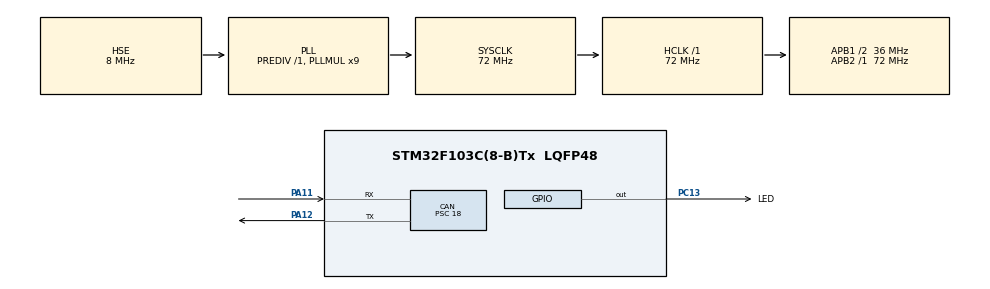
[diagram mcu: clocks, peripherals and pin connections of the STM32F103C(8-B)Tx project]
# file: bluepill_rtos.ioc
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CAN.BS1=CAN_BS1_14TQ
CAN.BS2=CAN_BS2_5TQ
CAN.CalculateBaudRate=100000
CAN.CalculateTimeBit=10000.00
CAN.CalculateTimeQuantum=500.0
CAN.Prescaler=18
FREERTOS.Tasks01=defaultTask,0,128,StartDefaultTask,Default,NULL,Dynamic,NULL,NULL;myTask02,-3,128,StartTask02,Default,NULL,Dynamic,NULL,NULL;myTask03,-3,128,StartTask03,Default,NULL,Dynamic,NULL,NULL
Mcu.Family=STM32F1
Mcu.Name=STM32F103C(8-B)Tx
Mcu.Package=LQFP48
NVIC.PriorityGroup=NVIC_PRIORITYGROUP_4
NVIC.TIM1_UP_IRQn=true\:0\:0\:false\:false\:true\:false\:false\:true
NVIC.TimeBase=TIM1_UP_IRQn
NVIC.TimeBaseIP=TIM1
NVIC.USB_LP_CAN1_RX0_IRQn=true\:5\:0\:false\:false\:true\:true\:true\:true
PA11.Mode=CAN_Activate
PA11.Signal=CAN_RX
PA12.Mode=CAN_Activate
PA12.Signal=CAN_TX
PA13.Mode=Serial_Wire
PA13.Signal=SYS_JTMS-SWDIO
PA14.Mode=Serial_Wire
PA14.Signal=SYS_JTCK-SWCLK
PC13-TAMPER-RTC.GPIO_Label=LED
PC13-TAMPER-RTC.Signal=GPIO_Output
PD0-OSC_IN.Mode=HSE-External-Oscillator
PD0-OSC_IN.Signal=RCC_OSC_IN
PD1-OSC_OUT.Mode=HSE-External-Oscillator
PD1-OSC_OUT.Signal=RCC_OSC_OUT
ProjectManager.HeapSize=0x200
ProjectManager.StackSize=0x400
ProjectManager.TargetToolchain=MDK-ARM V5
RCC.AHBFreq_Value=72000000
RCC.APB1CLKDivider=RCC_HCLK_DIV2
RCC.APB1Freq_Value=36000000
RCC.APB1TimFreq_Value=72000000
RCC.APB2Freq_Value=72000000
RCC.APB2TimFreq_Value=72000000
RCC.HCLKFreq_Value=72000000
RCC.PLLMUL=RCC_PLL_MUL9
RCC.PLLSourceVirtual=RCC_PLLSOURCE_HSE
RCC.SYSCLKFreq_VALUE=72000000
RCC.SYSCLKSource=RCC_SYSCLKSOURCE_PLLCLK
RCC.USBFreq_Value=72000000
VP_FREERTOS_VS_CMSIS_V1.Mode=CMSIS_V1
VP_SYS_VS_tim1.Mode=TIM1
board=custom

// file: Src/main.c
/* USER CODE BEGIN Header */
/**
  ******************************************************************************
  * @file           : main.c
  * @brief          : Main program body
  ******************************************************************************
  * @attention
  *
  * <h2><center>&copy; Copyright (c) 2021 STMicroelectronics.
  * All rights reserved.</center></h2>
  *
  * This software component is licensed by ST under Ultimate Liberty license
  * SLA0044, the "License"; You may not use this file except in compliance with
  * the License. You may obtain a copy of the License at:
  *                             www.st.com/SLA0044
  *
  ******************************************************************************
  */
/* USER CODE END Header */
#include "main.h"
#include "cmsis_os.h"
#include "can.h"
#include "gpio.h"
#include "time.h" //사용자 지정
#include <stdio.h> //지정하고 있는 라이브러리 경로

/* USER CODE BEGIN PV */
volatile uint8_t can1_rx0_flag =0; //컴파일러에게 최적화 x

/* USER CODE END PV */

void SystemClock_Config(void);
void MX_FREERTOS_Init(void);

/* USER CODE BEGIN 0 */
uint8_t tt=0;
char str[10];
/* USER CODE END 0 */

int main(void)
{

  /* MCU Configuration--------------------------------------------------------*/

  /* Reset of all peripherals, Initializes the Flash interface and the Systick. */
  HAL_Init();

  /* Configure the system clock */
  SystemClock_Config();

  /* Initialize all configured peripherals */
  MX_GPIO_Init();
  MX_CAN_Init();
  /* USER CODE BEGIN 2 */

	/*receive code 102,106,10A,10E 수신 */
	canFilter1.FilterMaskIdHigh = 0x7F3 <<5; //레지스터 id부분 상위11비트에 할당
	canFilter1.FilterIdHigh= 0x106 <<5; //5bit 쉬프트
	canFilter1.FilterMaskIdLow = 0x7F3 <<5; //레지스터 id부분 상위11비트에 할당
	canFilter1.FilterIdLow= 0x106 <<5; //5bit 쉬프트

	canFilter1.FilterMode = CAN_FILTERMODE_IDMASK;
	canFilter1.FilterScale = CAN_FILTERSCALE_16BIT;
	canFilter1.FilterFIFOAssignment = CAN_FilterFIFO0; //data저장
	canFilter1.FilterBank = 0;
	canFilter1.FilterActivation = ENABLE;

	HAL_CAN_ConfigFilter(&hcan1, &canFilter1);//can채널넘버, 필터설정값
	HAL_CAN_ActivateNotification(&hcan1, CAN_IT_RX_FIFO0_MSG_PENDING);	//인터럽트 걸리게 설정
	HAL_CAN_Start(&hcan1);
  /* USER CODE END 2 */

  /* Call init function for freertos objects (in freertos.c) */
  MX_FREERTOS_Init();
  /* Start scheduler */
  osKernelStart();

  /* We should never get here as control is now taken by the scheduler */
  /* Infinite loop */
  /* USER CODE BEGIN WHILE */
  while (1)
  {
		if(can1_rx0_flag) //수신된 메세지가 있으면
		{
			sprintf(str, "RX ID: 0x%3X", canRxHeader.StdId);
			sprintf(str, "RX ID: 0x%3X", can1RX0Data[0]);
		}
		if(tt==1)
		{
			tt=0;
			canTXHeader.StdId = 0x102;
			canTXHeader.RTR = CAN_RTR_DATA;
			canTXHeader.IDE = CAN_ID_STD;
			canTXHeader.DLC = 8;

			for(int i=0;i<8;i++) can1Tx0Data[i]++;

			TxMailBox = HAL_CAN_GetTxMailboxesFreeLevel(&hcan1);  //메일박스에 데이터 저장
			HAL_CAN_AddTxMessage(&hcan1,&canTXHeader,&can1Tx0Data[0],&TxMailBox);		//데이터 전송, 마지막 메일박스 번호
		}

    /* USER CODE END WHILE */

  }
}

void SystemClock_Config(void)
{
  RCC_OscInitTypeDef RCC_OscInitStruct = {0};
  RCC_ClkInitTypeDef RCC_ClkInitStruct = {0};

  /** Initializes the RCC Oscillators according to the specified parameters
  * in the RCC_OscInitTypeDef structure.
  */
  RCC_OscInitStruct.OscillatorType = RCC_OSCILLATORTYPE_HSE;
  RCC_OscInitStruct.HSEState = RCC_HSE_ON;
  RCC_OscInitStruct.HSEPredivValue = RCC_HSE_PREDIV_DIV1;
  RCC_OscInitStruct.HSIState = RCC_HSI_ON;
  RCC_OscInitStruct.PLL.PLLState = RCC_PLL_ON;
  RCC_OscInitStruct.PLL.PLLSource = RCC_PLLSOURCE_HSE;
  RCC_OscInitStruct.PLL.PLLMUL = RCC_PLL_MUL9;
  if (HAL_RCC_OscConfig(&RCC_OscInitStruct) != HAL_OK)
  {
    Error_Handler();
  }
  /** Initializes the CPU, AHB and APB buses clocks
  */
  RCC_ClkInitStruct.ClockType = RCC_CLOCKTYPE_HCLK|RCC_CLOCKTYPE_SYSCLK
                              |RCC_CLOCKTYPE_PCLK1|RCC_CLOCKTYPE_PCLK2;
  RCC_ClkInitStruct.SYSCLKSource = RCC_SYSCLKSOURCE_PLLCLK;
  RCC_ClkInitStruct.AHBCLKDivider = RCC_SYSCLK_DIV1;
  RCC_ClkInitStruct.APB1CLKDivider = RCC_HCLK_DIV2;
  RCC_ClkInitStruct.APB2CLKDivider = RCC_HCLK_DIV1;

  if (HAL_RCC_ClockConfig(&RCC_ClkInitStruct, FLASH_LATENCY_2) != HAL_OK)
  {
    Error_Handler();
  }
}

/* USER CODE BEGIN 4 */
void  HAL_CAN_RxFIfo0MsgPendingCallback(CAN_HandleTypeDef *hcan)
{
	if(hcan ->Instance == CAN1)
	{
		HAL_CAN_GetRxMessage(&hcan1, CAN_RX_FIFO0, &canRxHeader, &can1RX0Data[0]);
		can1_rx0_flag =1; //인터럽트 걸리면 변수 1 set
	}

}
/* USER CODE END 4 */

 /**
  * @brief  Period elapsed callback in non blocking mode
  * @note   This function is called  when TIM1 interrupt took place, inside
  * HAL_TIM_IRQHandler(). It makes a direct call to HAL_IncTick() to increment
  * a global variable "uwTick" used as application time base.
  * @param  htim : TIM handle
  * @retval None
  */
void HAL_TIM_PeriodElapsedCallback(TIM_HandleTypeDef *htim)
{
  if (htim->Instance == TIM1) {
    HAL_IncTick();
  }
}

void Error_Handler(void)
{
  __disable_irq();
  while (1)
  {
  }
}

/************************ (C) COPYRIGHT STMicroelectronics *****END OF FILE****/

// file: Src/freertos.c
/* USER CODE BEGIN Header */
/**
  ******************************************************************************
  * File Name          : freertos.c
  * Description        : Code for freertos applications
  ******************************************************************************
  * @attention
  *
  * <h2><center>&copy; Copyright (c) 2021 STMicroelectronics.
  * All rights reserved.</center></h2>
  *
  * This software component is licensed by ST under Ultimate Liberty license
  * SLA0044, the "License"; You may not use this file except in compliance with
  * the License. You may obtain a copy of the License at:
  *                             www.st.com/SLA0044
  *
  ******************************************************************************
  */
/* USER CODE END Header */

#include "FreeRTOS.h"
#include "task.h"
#include "main.h"
#include "cmsis_os.h"

osThreadId defaultTaskHandle;
osThreadId myTask02Handle;
osThreadId myTask03Handle;

void StartDefaultTask(void const * argument);
void StartTask02(void const * argument);
void StartTask03(void const * argument);

void MX_FREERTOS_Init(void); /* (MISRA C 2004 rule 8.1) */

/* GetIdleTaskMemory prototype (linked to static allocation support) */
void vApplicationGetIdleTaskMemory( StaticTask_t **ppxIdleTaskTCBBuffer, StackType_t **ppxIdleTaskStackBuffer, uint32_t *pulIdleTaskStackSize );

/* USER CODE BEGIN GET_IDLE_TASK_MEMORY */
static StaticTask_t xIdleTaskTCBBuffer;
static StackType_t xIdleStack[configMINIMAL_STACK_SIZE];

void vApplicationGetIdleTaskMemory( StaticTask_t **ppxIdleTaskTCBBuffer, StackType_t **ppxIdleTaskStackBuffer, uint32_t *pulIdleTaskStackSize )
{
  *ppxIdleTaskTCBBuffer = &xIdleTaskTCBBuffer;
  *ppxIdleTaskStackBuffer = &xIdleStack[0];
  *pulIdleTaskStackSize = configMINIMAL_STACK_SIZE;
  /* place for user code */
}
/* USER CODE END GET_IDLE_TASK_MEMORY */

void MX_FREERTOS_Init(void) {

  /* Create the thread(s) */
  /* definition and creation of defaultTask */
  osThreadDef(defaultTask, StartDefaultTask, osPriorityNormal, 0, 128);
  defaultTaskHandle = osThreadCreate(osThread(defaultTask), NULL);

  /* definition and creation of myTask02 */
  osThreadDef(myTask02, StartTask02, osPriorityIdle, 0, 128);
  myTask02Handle = osThreadCreate(osThread(myTask02), NULL);

  /* definition and creation of myTask03 */
  osThreadDef(myTask03, StartTask03, osPriorityIdle, 0, 128);
  myTask03Handle = osThreadCreate(osThread(myTask03), NULL);

}

void StartDefaultTask(void const * argument)
{
  /* USER CODE BEGIN StartDefaultTask */
  /* Infinite loop */
  for(;;)
  {
		//HAL_GPIO_TogglePin(GPIOC,GPIO_PIN_13);
    osDelay(1);
  }
  /* USER CODE END StartDefaultTask */
}

void StartTask02(void const * argument)
{
  for(;;)
  {
    osDelay(1);
  }
}

void StartTask03(void const * argument)
{
  /* USER CODE BEGIN StartTask03 */
  /* Infinite loop */
  for(;;)
  {
		HAL_GPIO_TogglePin(GPIOC,GPIO_PIN_13);
    osDelay(500);
  }
  /* USER CODE END StartTask03 */
}

/************************ (C) COPYRIGHT STMicroelectronics *****END OF FILE****/
